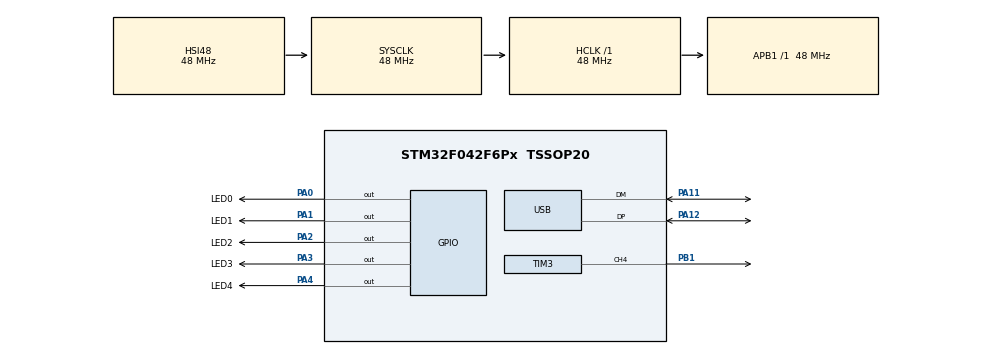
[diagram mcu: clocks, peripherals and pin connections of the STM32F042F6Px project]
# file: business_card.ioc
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Mcu.Family=STM32F0
Mcu.Name=STM32F042F6Px
Mcu.Package=TSSOP20
NVIC.USB_IRQn=true\:0\:0\:false\:false\:true\:false\:true\:true
PA0.GPIO_Label=LED0
PA0.Signal=GPIO_Output
PA1.GPIO_Label=LED1
PA1.Signal=GPIO_Output
PA11.Mode=Device
PA11.Signal=USB_DM
PA12.Mode=Device
PA12.Signal=USB_DP
PA13.Mode=Serial_Wire
PA13.Signal=SYS_SWDIO
PA14.Mode=Serial_Wire
PA14.Signal=SYS_SWCLK
PA2.GPIO_Label=LED2
PA2.Signal=GPIO_Output
PA3.GPIO_Label=LED3
PA3.Signal=GPIO_Output
PA4.GPIO_Label=LED4
PA4.Signal=GPIO_Output
PB1.Signal=S_TIM3_CH4
ProjectManager.HeapSize=0x200
ProjectManager.StackSize=0x400
ProjectManager.TargetToolchain=CMake
RCC.AHBFreq_Value=48000000
RCC.APB1Freq_Value=48000000
RCC.APB1TimFreq_Value=48000000
RCC.HCLKFreq_Value=48000000
RCC.PLLSourceVirtual=RCC_PLLSOURCE_HSI48
RCC.SYSCLKFreq_VALUE=48000000
RCC.SYSCLKSource=RCC_SYSCLKSOURCE_HSI48
SH.S_TIM3_CH4.0=TIM3_CH4,PWM Generation4 CH4
TIM3.Channel-PWM\ Generation4\ CH4=TIM_CHANNEL_4
TIM3.OC4Preload_PWM=DISABLE
TIM3.Period=6000
TIM3.Prescaler=47
TIM3.Pulse-PWM\ Generation4\ CH4=3000
USB_DEVICE.APP_RX_DATA_SIZE=128
USB_DEVICE.APP_TX_DATA_SIZE=128
USB_DEVICE.CLASS_NAME_FS=CDC
USB_DEVICE.USBD_MAX_STR_DESC_SIZ=64
USB_DEVICE.VirtualMode=Cdc
USB_DEVICE.VirtualModeFS=Cdc_FS
VP_SYS_VS_PINREMAP.Mode=PINREMAP
VP_TIM3_VS_ClockSourceINT.Mode=Internal
VP_USB_DEVICE_VS_USB_DEVICE_CDC_FS.Mode=CDC_FS
board=custom

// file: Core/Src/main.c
/* USER CODE BEGIN Header */
/**
  ******************************************************************************
  * @file           : main.c
  * @brief          : Main program body
  ******************************************************************************
  * @attention
  *
  * Copyright (c) 2025 STMicroelectronics.
  * All rights reserved.
  *
  * This software is licensed under terms that can be found in the LICENSE file
  * in the root directory of this software component.
  * If no LICENSE file comes with this software, it is provided AS-IS.
  *
  ******************************************************************************
  */
/* USER CODE END Header */
#include "main.h"
#include "tim.h"
#include "usb_device.h"
#include "gpio.h"

/* USER CODE BEGIN Includes */
#include "notes.h"
#include "songs.h"
#include "usbd_cdc_if.h"
#include "user_notes.h"
#include "menu.h"
/* USER CODE END Includes */

void SystemClock_Config(void);

int main(void)
{

  /* USER CODE BEGIN 1 */
  //int8_t led_id = -1;
  /* USER CODE END 1 */

  /* MCU Configuration--------------------------------------------------------*/

  /* Reset of all peripherals, Initializes the Flash interface and the Systick. */
  HAL_Init();

  /* Configure the system clock */
  SystemClock_Config();

  /* Initialize all configured peripherals */
  MX_GPIO_Init();
  MX_TIM3_Init();
  MX_USB_DEVICE_Init();
  /* USER CODE BEGIN 2 */

  setupNotes(chngComp, chngTop, outOn, outOff);
  setBeat(200);
  HAL_TIM_PWM_Stop(&htim3, TIM_CHANNEL_4);

  /* USER CODE END 2 */

  /* Infinite loop */
  while (1)
  {

  }
}

void SystemClock_Config(void)
{
  RCC_OscInitTypeDef RCC_OscInitStruct = {0};
  RCC_ClkInitTypeDef RCC_ClkInitStruct = {0};
  RCC_PeriphCLKInitTypeDef PeriphClkInit = {0};

  /** Initializes the RCC Oscillators according to the specified parameters
  * in the RCC_OscInitTypeDef structure.
  */
  RCC_OscInitStruct.OscillatorType = RCC_OSCILLATORTYPE_HSI48;
  RCC_OscInitStruct.HSI48State = RCC_HSI48_ON;
  RCC_OscInitStruct.PLL.PLLState = RCC_PLL_NONE;
  if (HAL_RCC_OscConfig(&RCC_OscInitStruct) != HAL_OK)
  {
    Error_Handler();
  }

  /** Initializes the CPU, AHB and APB buses clocks
  */
  RCC_ClkInitStruct.ClockType = RCC_CLOCKTYPE_HCLK|RCC_CLOCKTYPE_SYSCLK
                              |RCC_CLOCKTYPE_PCLK1;
  RCC_ClkInitStruct.SYSCLKSource = RCC_SYSCLKSOURCE_HSI48;
  RCC_ClkInitStruct.AHBCLKDivider = RCC_SYSCLK_DIV1;
  RCC_ClkInitStruct.APB1CLKDivider = RCC_HCLK_DIV1;

  if (HAL_RCC_ClockConfig(&RCC_ClkInitStruct, FLASH_LATENCY_1) != HAL_OK)
  {
    Error_Handler();
  }
  PeriphClkInit.PeriphClockSelection = RCC_PERIPHCLK_USB;
  PeriphClkInit.UsbClockSelection = RCC_USBCLKSOURCE_HSI48;

  if (HAL_RCCEx_PeriphCLKConfig(&PeriphClkInit) != HAL_OK)
  {
    Error_Handler();
  }
}

void Error_Handler(void)
{
  __disable_irq();
  while (1)
  {
  }
}
